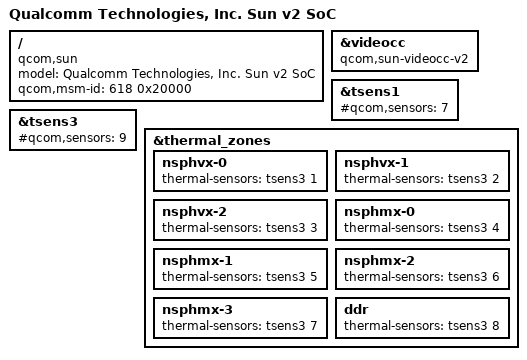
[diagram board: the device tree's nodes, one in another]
// SPDX-License-Identifier: BSD-3-Clause
/*
 * Copyright (c) 2023-2024, Qualcomm Innovation Center, Inc. All rights reserved.
 */
#include "sun.dtsi"

/ {
	model = "Qualcomm Technologies, Inc. Sun v2 SoC";
	compatible = "qcom,sun";
	qcom,msm-id = <618 0x20000>;
};

&videocc {
	compatible = "qcom,sun-videocc-v2", "syscon";
};

&tsens1 {
	#qcom,sensors = <7>;
};

&tsens3 {
	#qcom,sensors = <9>;
};

&thermal_zones {
	nsphvx-0 {
		thermal-sensors = <&tsens3 1>;
	};

	nsphvx-1 {
		thermal-sensors = <&tsens3 2>;
	};

	nsphvx-2 {
		thermal-sensors = <&tsens3 3>;
	};

	nsphmx-0 {
		thermal-sensors = <&tsens3 4>;
	};

	nsphmx-1 {
		thermal-sensors = <&tsens3 5>;
	};

	nsphmx-2 {
		thermal-sensors = <&tsens3 6>;
	};

	nsphmx-3 {
		thermal-sensors = <&tsens3 7>;
	};

	ddr {
		thermal-sensors = <&tsens3 8>;
	};
};
